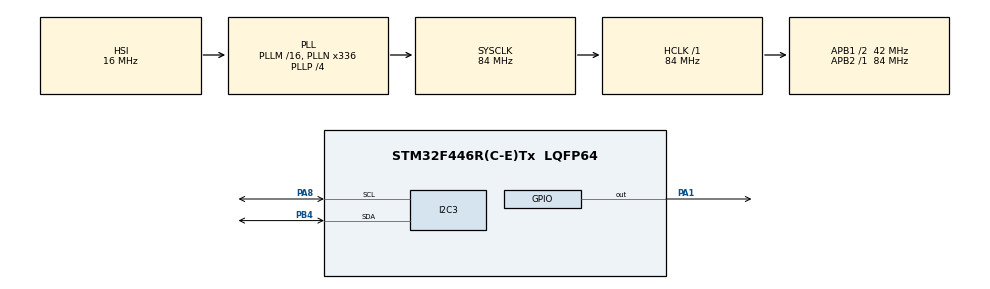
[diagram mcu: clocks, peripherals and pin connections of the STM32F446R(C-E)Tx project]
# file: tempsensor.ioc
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Dma.I2C3_RX.1.Direction=DMA_PERIPH_TO_MEMORY
Dma.I2C3_RX.1.FIFOMode=DMA_FIFOMODE_DISABLE
Dma.I2C3_RX.1.Instance=DMA1_Stream1
Dma.I2C3_RX.1.MemDataAlignment=DMA_MDATAALIGN_BYTE
Dma.I2C3_RX.1.MemInc=DMA_MINC_ENABLE
Dma.I2C3_RX.1.Mode=DMA_NORMAL
Dma.I2C3_RX.1.PeriphDataAlignment=DMA_PDATAALIGN_BYTE
Dma.I2C3_RX.1.PeriphInc=DMA_PINC_DISABLE
Dma.I2C3_RX.1.Priority=DMA_PRIORITY_LOW
Dma.I2C3_TX.0.Direction=DMA_MEMORY_TO_PERIPH
Dma.I2C3_TX.0.FIFOMode=DMA_FIFOMODE_DISABLE
Dma.I2C3_TX.0.Instance=DMA1_Stream4
Dma.I2C3_TX.0.MemDataAlignment=DMA_MDATAALIGN_BYTE
Dma.I2C3_TX.0.MemInc=DMA_MINC_ENABLE
Dma.I2C3_TX.0.Mode=DMA_NORMAL
Dma.I2C3_TX.0.PeriphDataAlignment=DMA_PDATAALIGN_BYTE
Dma.I2C3_TX.0.PeriphInc=DMA_PINC_DISABLE
Dma.I2C3_TX.0.Priority=DMA_PRIORITY_LOW
Dma.Request0=I2C3_TX
Dma.Request1=I2C3_RX
Mcu.Family=STM32F4
Mcu.Name=STM32F446R(C-E)Tx
Mcu.Package=LQFP64
NVIC.DMA1_Stream1_IRQn=true\:0\:0\:false\:false\:true\:false\:true\:true
NVIC.DMA1_Stream4_IRQn=true\:0\:0\:false\:false\:true\:false\:true\:true
NVIC.I2C3_EV_IRQn=true\:0\:0\:false\:false\:true\:true\:true\:true
NVIC.PriorityGroup=NVIC_PRIORITYGROUP_0
PA1.Signal=GPIO_Output
PA13.Mode=Serial_Wire
PA13.Signal=SYS_JTMS-SWDIO
PA14.Mode=Serial_Wire
PA14.Signal=SYS_JTCK-SWCLK
PA8.GPIO_Pu=GPIO_PULLUP
PA8.Mode=I2C
PA8.Signal=I2C3_SCL
PB4.GPIO_Pu=GPIO_PULLUP
PB4.Mode=I2C
PB4.Signal=I2C3_SDA
ProjectManager.HeapSize=0x200
ProjectManager.StackSize=0x400
ProjectManager.TargetToolchain=STM32CubeIDE
RCC.48MHZClocksFreq_Value=84000000
RCC.AHBFreq_Value=84000000
RCC.APB1CLKDivider=RCC_HCLK_DIV2
RCC.APB1Freq_Value=42000000
RCC.APB1TimFreq_Value=84000000
RCC.APB2Freq_Value=84000000
RCC.APB2TimFreq_Value=84000000
RCC.CortexFreq_Value=84000000
RCC.FLatency-AdvancedSettings=FLASH_LATENCY_2
RCC.HCLKFreq_Value=84000000
RCC.HSE_VALUE=8000000
RCC.HSI_VALUE=16000000
RCC.PLLN=336
RCC.PLLP=RCC_PLLP_DIV4
RCC.SYSCLKFreq_VALUE=84000000
RCC.SYSCLKSource=RCC_SYSCLKSOURCE_PLLCLK
RCC.USBFreq_Value=168000000
RCC.VCOOutputFreq_Value=336000000
VP_RTC_VS_RTC_Activate.Mode=RTC_Enabled
VP_RTC_VS_RTC_Calendar.Mode=RTC_Calendar
VP_RTC_VS_RTC_WakeUp_intern.Mode=WakeUp
board=NUCLEO-F446RE

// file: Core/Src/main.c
/* USER CODE BEGIN Header */
/**
  ******************************************************************************
  * @file           : main.c
  * @brief          : Main program body
  ******************************************************************************
  * @attention
  *
  * Copyright (c) 2023 STMicroelectronics.
  * All rights reserved.
  *
  * This software is licensed under terms that can be found in the LICENSE file
  * in the root directory of this software component.
  * If no LICENSE file comes with this software, it is provided AS-IS.
  *
  ******************************************************************************
  */
/* USER CODE END Header */
#include "main.h"

/* USER CODE BEGIN Includes */
#include <string.h>
#include <stdio.h>
#include "ssd1306.h"
#include "DHT.h"

/* USER CODE END Includes */

/* USER CODE BEGIN PD */

#define C_TO_F(x) ((x * 9.f/5) + 32)

/* USER CODE END PD */

I2C_HandleTypeDef hi2c3;
DMA_HandleTypeDef hdma_i2c3_tx;
DMA_HandleTypeDef hdma_i2c3_rx;

RTC_HandleTypeDef hrtc;

void SystemClock_Config(void);
static void MX_GPIO_Init(void);
static void MX_DMA_Init(void);
static void MX_I2C3_Init(void);
static void MX_RTC_Init(void);
/* USER CODE BEGIN PFP */

static void update_display(DHT_DataTypedef *dht11);

/* USER CODE END PFP */

int main(void)
{

  /* MCU Configuration--------------------------------------------------------*/

  /* Reset of all peripherals, Initializes the Flash interface and the Systick. */
  HAL_Init();

  /* Configure the system clock */
  SystemClock_Config();

  /* Initialize all configured peripherals */
  MX_GPIO_Init();
  MX_DMA_Init();
  MX_I2C3_Init();
  MX_RTC_Init();
  /* USER CODE BEGIN 2 */

	ssd1306_Init();

	DHT_DataTypedef dht11;

  /* USER CODE END 2 */

  /* Infinite loop */
	while (1) {

    /* USER CODE BEGIN 3 */
		DHT_GetData(&dht11);

		update_display(&dht11);
		HAL_Delay(100);

	}
  /* USER CODE END 3 */
}

void SystemClock_Config(void)
{
  RCC_OscInitTypeDef RCC_OscInitStruct = {0};
  RCC_ClkInitTypeDef RCC_ClkInitStruct = {0};

  /** Configure the main internal regulator output voltage
  */
  __HAL_RCC_PWR_CLK_ENABLE();
  __HAL_PWR_VOLTAGESCALING_CONFIG(PWR_REGULATOR_VOLTAGE_SCALE3);

  /** Initializes the RCC Oscillators according to the specified parameters
  * in the RCC_OscInitTypeDef structure.
  */
  RCC_OscInitStruct.OscillatorType = RCC_OSCILLATORTYPE_HSI|RCC_OSCILLATORTYPE_LSI;
  RCC_OscInitStruct.LSEState = RCC_LSE_OFF;
  RCC_OscInitStruct.HSIState = RCC_HSI_ON;
  RCC_OscInitStruct.HSICalibrationValue = RCC_HSICALIBRATION_DEFAULT;
  RCC_OscInitStruct.LSIState = RCC_LSI_ON;
  RCC_OscInitStruct.PLL.PLLState = RCC_PLL_ON;
  RCC_OscInitStruct.PLL.PLLSource = RCC_PLLSOURCE_HSI;
  RCC_OscInitStruct.PLL.PLLM = 16;
  RCC_OscInitStruct.PLL.PLLN = 336;
  RCC_OscInitStruct.PLL.PLLP = RCC_PLLP_DIV4;
  RCC_OscInitStruct.PLL.PLLQ = 2;
  RCC_OscInitStruct.PLL.PLLR = 2;
  if (HAL_RCC_OscConfig(&RCC_OscInitStruct) != HAL_OK)
  {
    Error_Handler();
  }

  /** Initializes the CPU, AHB and APB buses clocks
  */
  RCC_ClkInitStruct.ClockType = RCC_CLOCKTYPE_HCLK|RCC_CLOCKTYPE_SYSCLK
                              |RCC_CLOCKTYPE_PCLK1|RCC_CLOCKTYPE_PCLK2;
  RCC_ClkInitStruct.SYSCLKSource = RCC_SYSCLKSOURCE_PLLCLK;
  RCC_ClkInitStruct.AHBCLKDivider = RCC_SYSCLK_DIV1;
  RCC_ClkInitStruct.APB1CLKDivider = RCC_HCLK_DIV2;
  RCC_ClkInitStruct.APB2CLKDivider = RCC_HCLK_DIV1;

  if (HAL_RCC_ClockConfig(&RCC_ClkInitStruct, FLASH_LATENCY_2) != HAL_OK)
  {
    Error_Handler();
  }
}

static void MX_I2C3_Init(void)
{

  hi2c3.Instance = I2C3;
  hi2c3.Init.ClockSpeed = 100000;
  hi2c3.Init.DutyCycle = I2C_DUTYCYCLE_2;
  hi2c3.Init.OwnAddress1 = 0;
  hi2c3.Init.AddressingMode = I2C_ADDRESSINGMODE_7BIT;
  hi2c3.Init.DualAddressMode = I2C_DUALADDRESS_DISABLE;
  hi2c3.Init.OwnAddress2 = 0;
  hi2c3.Init.GeneralCallMode = I2C_GENERALCALL_DISABLE;
  hi2c3.Init.NoStretchMode = I2C_NOSTRETCH_DISABLE;
  if (HAL_I2C_Init(&hi2c3) != HAL_OK)
  {
    Error_Handler();
  }

}

static void MX_RTC_Init(void)
{

  RTC_TimeTypeDef sTime = {0};
  RTC_DateTypeDef sDate = {0};

  /** Initialize RTC Only
  */
  hrtc.Instance = RTC;
  hrtc.Init.HourFormat = RTC_HOURFORMAT_24;
  hrtc.Init.AsynchPrediv = 127;
  hrtc.Init.SynchPrediv = 255;
  hrtc.Init.OutPut = RTC_OUTPUT_DISABLE;
  hrtc.Init.OutPutPolarity = RTC_OUTPUT_POLARITY_HIGH;
  hrtc.Init.OutPutType = RTC_OUTPUT_TYPE_OPENDRAIN;
  if (HAL_RTC_Init(&hrtc) != HAL_OK)
  {
    Error_Handler();
  }

  /** Initialize RTC and set the Time and Date
  */
  sTime.Hours = 0x0;
  sTime.Minutes = 0x0;
  sTime.Seconds = 0x0;
  sTime.DayLightSaving = RTC_DAYLIGHTSAVING_NONE;
  sTime.StoreOperation = RTC_STOREOPERATION_RESET;
  if (HAL_RTC_SetTime(&hrtc, &sTime, RTC_FORMAT_BCD) != HAL_OK)
  {
    Error_Handler();
  }
  sDate.WeekDay = RTC_WEEKDAY_MONDAY;
  sDate.Month = RTC_MONTH_JANUARY;
  sDate.Date = 0x1;
  sDate.Year = 0x0;

  if (HAL_RTC_SetDate(&hrtc, &sDate, RTC_FORMAT_BCD) != HAL_OK)
  {
    Error_Handler();
  }

  /** Enable the WakeUp
  */
  if (HAL_RTCEx_SetWakeUpTimer(&hrtc, 0, RTC_WAKEUPCLOCK_RTCCLK_DIV16) != HAL_OK)
  {
    Error_Handler();
  }

}

static void MX_DMA_Init(void)
{

  /* DMA controller clock enable */
  __HAL_RCC_DMA1_CLK_ENABLE();

  /* DMA interrupt init */
  /* DMA1_Stream1_IRQn interrupt configuration */
  HAL_NVIC_SetPriority(DMA1_Stream1_IRQn, 0, 0);
  HAL_NVIC_EnableIRQ(DMA1_Stream1_IRQn);
  /* DMA1_Stream4_IRQn interrupt configuration */
  HAL_NVIC_SetPriority(DMA1_Stream4_IRQn, 0, 0);
  HAL_NVIC_EnableIRQ(DMA1_Stream4_IRQn);

}

static void MX_GPIO_Init(void)
{
  GPIO_InitTypeDef GPIO_InitStruct = {0};

  /* GPIO Ports Clock Enable */
  __HAL_RCC_GPIOA_CLK_ENABLE();
  __HAL_RCC_GPIOB_CLK_ENABLE();

  /*Configure GPIO pin Output Level */
  HAL_GPIO_WritePin(GPIOA, GPIO_PIN_1, GPIO_PIN_RESET);

  /*Configure GPIO pin : PA1 */
  GPIO_InitStruct.Pin = GPIO_PIN_1;
  GPIO_InitStruct.Mode = GPIO_MODE_OUTPUT_PP;
  GPIO_InitStruct.Pull = GPIO_NOPULL;
  GPIO_InitStruct.Speed = GPIO_SPEED_FREQ_LOW;
  HAL_GPIO_Init(GPIOA, &GPIO_InitStruct);

}

/* USER CODE BEGIN 4 */

static void write_blue_line(char *msg, int row) {
	ssd1306_SetCursor(0, 16 + row * 18);
	ssd1306_WriteString(msg, Font_11x18, Black);
}

static void write_header_line(char *msg) {
	ssd1306_SetCursor(0, 0);
	ssd1306_WriteString(msg, Font_11x18, Black);
}

static void update_display(DHT_DataTypedef *dht11) {
	int t = (int)C_TO_F(dht11->Temperature);
	int h = (int)dht11->Humidity;

	char t_str[100] = {0};
	char h_str[100] = {0};

	sprintf(t_str, "%d F", t);
	sprintf(h_str, "%d%% H", h);

	ssd1306_Fill(White);
	write_header_line("TEMP/HUMID");
	write_blue_line(t_str, 0);
	write_blue_line(h_str, 1);
    ssd1306_UpdateScreen();
}

/* USER CODE END 4 */

void Error_Handler(void)
{
  __disable_irq();
  while (1)
  {
  }
}
